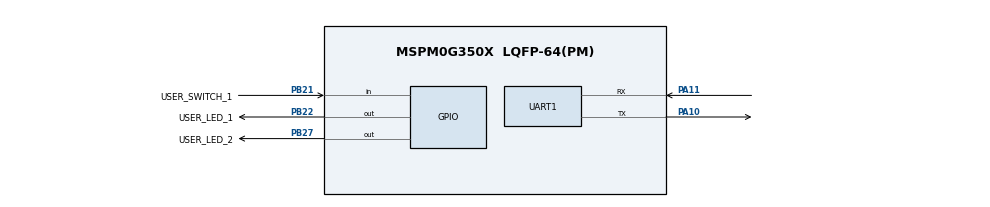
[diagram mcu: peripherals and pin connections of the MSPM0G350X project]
// @cliArgs --device "MSPM0G350X" --package "LQFP-64(PM)" --part "Default"
// @cliArgs --board /ti/boards/LP_MSPM0G3507 --rtos nortos

/**
 * Import the modules used in this configuration.
 */
const GPIO          = scripting.addModule("/ti/driverlib/GPIO", {}, false);
const GPIO1         = GPIO.addInstance();
const GPIO2         = GPIO.addInstance();
const UART          = scripting.addModule("/ti/driverlib/UART", {}, false);
const UART1         = UART.addInstance();
const ProjectConfig = scripting.addModule("/ti/project_config/ProjectConfig");

/**
 * Write custom configuration values to the imported modules.
 */
GPIO1.$name                         = "GPIO_LEDS";
GPIO1.associatedPins.create(2);
GPIO1.associatedPins[0].$name       = "USER_LED_1";
GPIO1.associatedPins[0].pin.$assign = "PB22";
GPIO1.associatedPins[1].$name       = "USER_LED_2";
GPIO1.associatedPins[1].pin.$assign = "PB27";

const Board = scripting.addModule("/ti/driverlib/Board", {}, false);

GPIO2.$name                              = "GPIO_SWITCHES";
GPIO2.associatedPins[0].direction        = "INPUT";
GPIO2.associatedPins[0].interruptEn      = true;
GPIO2.associatedPins[0].polarity         = "FALL";
GPIO2.associatedPins[0].internalResistor = "PULL_UP";
GPIO2.associatedPins[0].$name            = "USER_SWITCH_1";
GPIO2.associatedPins[0].pin.$assign      = "PB21";

const SYSCTL = scripting.addModule("/ti/driverlib/SYSCTL", {}, false);

UART1.$name                    = "UART_0";
UART1.enabledInterrupts        = ["RX"];
UART1.peripheral.rxPin.$assign = "PA11";
UART1.peripheral.txPin.$assign = "PA10";

ProjectConfig.genLinker = false;
scripting.suppress("All four File Generation options must be enabled in order to guarantee Device Migration support\\. If an option is disabled, the user must manually configure that setting on its own file\\.", ProjectConfig);
